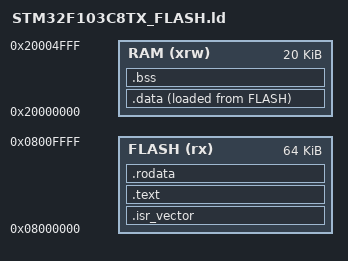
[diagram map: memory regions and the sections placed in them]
/* Linker script for STM32F103C8T6 (64KB Flash, 20KB RAM) */
ENTRY(Reset_Handler)

/* Top of RAM = initial stack pointer */
_estack = ORIGIN(RAM) + LENGTH(RAM);  /* 0x20005000 */

MEMORY
{
    FLASH (rx)  : ORIGIN = 0x08000000, LENGTH = 64K
    RAM   (xrw) : ORIGIN = 0x20000000, LENGTH = 20K
}

SECTIONS
{
    .isr_vector :
    {
        . = ALIGN(4);
        KEEP(*(.isr_vector))
        . = ALIGN(4);
    } >FLASH

    .text :
    {
        . = ALIGN(4);
        *(.text)
        *(.text*)
        *(.glue_7)
        *(.glue_7t)
        *(.eh_frame)
        KEEP (*(.init))
        KEEP (*(.fini))
        . = ALIGN(4);
        _etext = .;
    } >FLASH

    .rodata :
    {
        . = ALIGN(4);
        *(.rodata)
        *(.rodata*)
        . = ALIGN(4);
    } >FLASH

    .data :
    {
        . = ALIGN(4);
        _sdata = .;
        _sidata = LOADADDR(.data);
        *(.data)
        *(.data*)
        . = ALIGN(4);
        _edata = .;
    } >RAM AT> FLASH

    .bss :
    {
        . = ALIGN(4);
        _sbss = .;
        __bss_start__ = _sbss;
        *(.bss)
        *(.bss*)
        *(COMMON)
        . = ALIGN(4);
        _ebss = .;
        __bss_end__ = _ebss;
    } >RAM

    /DISCARD/ :
    {
        libc.a ( * )
        libm.a ( * )
        libgcc.a ( * )
    }
}
